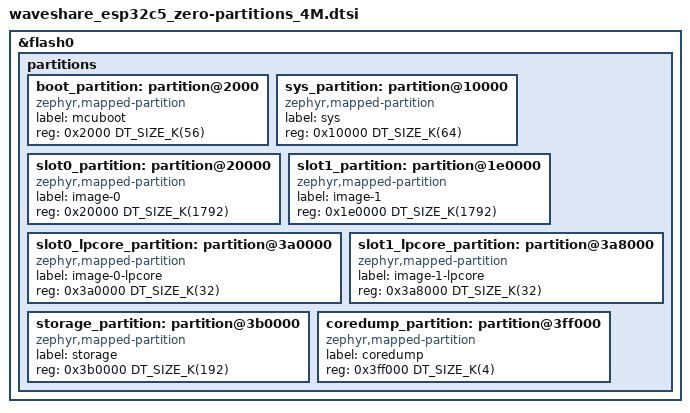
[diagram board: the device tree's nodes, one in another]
/*
 * Copyright (c) 2024-2026 Espressif Systems (Shanghai) Co., Ltd.
 *
 * SPDX-License-Identifier: GPL-3.0-or-later
 *
 * Espressif's 4 MB default table with the C5's 0x2000 boot offset (the ROM
 * keeps the first two sectors), as their 8 MB table for the C5 does.
 */

&flash0 {
	partitions {
		ranges;
		#address-cells = <1>;
		#size-cells = <1>;

		boot_partition: partition@2000 {
			compatible = "zephyr,mapped-partition";
			label = "mcuboot";
			reg = <0x2000 DT_SIZE_K(56)>;
		};

		sys_partition: partition@10000 {
			compatible = "zephyr,mapped-partition";
			label = "sys";
			reg = <0x10000 DT_SIZE_K(64)>;
		};

		slot0_partition: partition@20000 {
			compatible = "zephyr,mapped-partition";
			label = "image-0";
			reg = <0x20000 DT_SIZE_K(1792)>;
		};

		slot1_partition: partition@1e0000 {
			compatible = "zephyr,mapped-partition";
			label = "image-1";
			reg = <0x1e0000 DT_SIZE_K(1792)>;
		};

		slot0_lpcore_partition: partition@3a0000 {
			compatible = "zephyr,mapped-partition";
			label = "image-0-lpcore";
			reg = <0x3a0000 DT_SIZE_K(32)>;
		};

		slot1_lpcore_partition: partition@3a8000 {
			compatible = "zephyr,mapped-partition";
			label = "image-1-lpcore";
			reg = <0x3a8000 DT_SIZE_K(32)>;
		};

		storage_partition: partition@3b0000 {
			compatible = "zephyr,mapped-partition";
			label = "storage";
			reg = <0x3b0000 DT_SIZE_K(192)>;
		};

		coredump_partition: partition@3ff000 {
			compatible = "zephyr,mapped-partition";
			label = "coredump";
			reg = <0x3ff000 DT_SIZE_K(4)>;
		};
	};
};
